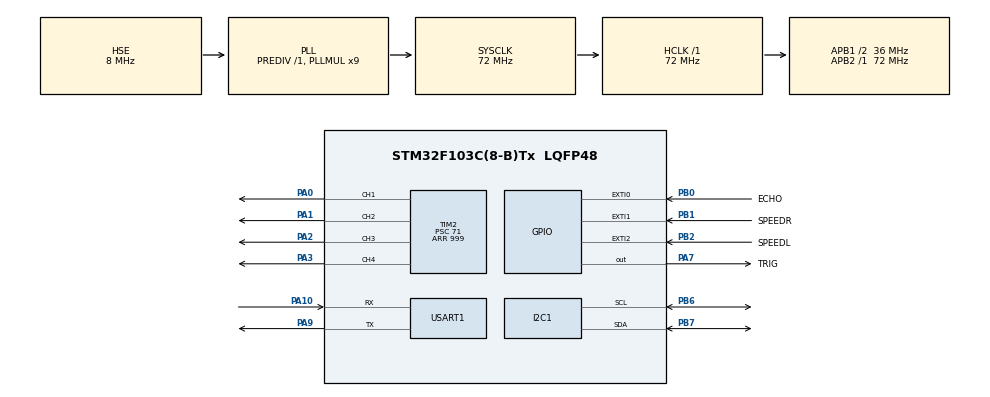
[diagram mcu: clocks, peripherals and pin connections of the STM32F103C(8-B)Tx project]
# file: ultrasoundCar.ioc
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IWDG.Prescaler=IWDG_PRESCALER_32
Mcu.Family=STM32F1
Mcu.Name=STM32F103C(8-B)Tx
Mcu.Package=LQFP48
NVIC.PriorityGroup=NVIC_PRIORITYGROUP_4
NVIC.TIM3_IRQn=true\:0\:0\:false\:false\:true
PA0-WKUP.Signal=S_TIM2_CH1_ETR
PA1.Signal=S_TIM2_CH2
PA10.Mode=Asynchronous
PA10.Signal=USART1_RX
PA13.Mode=Serial_Wire
PA13.Signal=SYS_JTMS-SWDIO
PA14.Mode=Serial_Wire
PA14.Signal=SYS_JTCK-SWCLK
PA2.Signal=S_TIM2_CH3
PA3.Signal=S_TIM2_CH4
PA7.GPIO_Label=TRIG
PA7.Signal=GPIO_Output
PA9.Mode=Asynchronous
PA9.Signal=USART1_TX
PB0.GPIO_Label=ECHO
PB0.Signal=GPXTI0
PB1.GPIO_Label=SPEEDR
PB1.Signal=GPXTI1
PB2.GPIO_Label=SPEEDL
PB2.Signal=GPXTI2
PB6.Mode=I2C
PB6.Signal=I2C1_SCL
PB7.Mode=I2C
PB7.Signal=I2C1_SDA
PD0-OSC_IN.Mode=HSE-External-Oscillator
PD0-OSC_IN.Signal=RCC_OSC_IN
PD1-OSC_OUT.Mode=HSE-External-Oscillator
PD1-OSC_OUT.Signal=RCC_OSC_OUT
ProjectManager.HeapSize=0x200
ProjectManager.StackSize=0x400
ProjectManager.TargetToolchain=SW4STM32
RCC.AHBFreq_Value=72000000
RCC.APB1CLKDivider=RCC_HCLK_DIV2
RCC.APB1Freq_Value=36000000
RCC.APB1TimFreq_Value=72000000
RCC.APB2Freq_Value=72000000
RCC.APB2TimFreq_Value=72000000
RCC.HCLKFreq_Value=72000000
RCC.HSIState=RCC_HSI_ON
RCC.PLLMUL=RCC_PLL_MUL9
RCC.PLLSourceVirtual=RCC_PLLSOURCE_HSE
RCC.SYSCLKFreq_VALUE=72000000
RCC.SYSCLKSource=RCC_SYSCLKSOURCE_PLLCLK
RCC.USBFreq_Value=72000000
SH.S_TIM2_CH1_ETR.0=TIM2_CH1,PWM Generation1 CH1
SH.S_TIM2_CH2.0=TIM2_CH2,PWM Generation2 CH2
SH.S_TIM2_CH3.0=TIM2_CH3,PWM Generation3 CH3
SH.S_TIM2_CH4.0=TIM2_CH4,PWM Generation4 CH4
TIM2.Channel-PWM\ Generation2\ CH2=TIM_CHANNEL_2
TIM2.Channel-PWM\ Generation3\ CH3=TIM_CHANNEL_3
TIM2.Channel-PWM\ Generation4\ CH4=TIM_CHANNEL_4
TIM2.Period=999
TIM2.Prescaler=71
TIM2.Pulse-PWM\ Generation1\ CH1=0
TIM2.Pulse-PWM\ Generation4\ CH4=0
VP_IWDG_VS_IWDG.Mode=IWDG_Activate
VP_TIM1_VS_ClockSourceINT.Mode=Internal
VP_TIM3_VS_ClockSourceINT.Mode=Internal
VP_TIM4_VS_ClockSourceINT.Mode=Internal
board=ultrasoundCar

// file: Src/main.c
/**
  ******************************************************************************
  * File Name          : main.c
  * Description        : Main program body
  ******************************************************************************
  *
  * COPYRIGHT(c) 2016 STMicroelectronics
  *
  * Redistribution and use in source and binary forms, with or without modification,
  * are permitted provided that the following conditions are met:
  *   1. Redistributions of source code must retain the above copyright notice,
  *      this list of conditions and the following disclaimer.
  *   2. Redistributions in binary form must reproduce the above copyright notice,
  *      this list of conditions and the following disclaimer in the documentation
  *      and/or other materials provided with the distribution.
  *   3. Neither the name of STMicroelectronics nor the names of its contributors
  *      may be used to endorse or promote products derived from this software
  *      without specific prior written permission.
  *
  * THIS SOFTWARE IS PROVIDED BY THE COPYRIGHT HOLDERS AND CONTRIBUTORS "AS IS"
  * AND ANY EXPRESS OR IMPLIED WARRANTIES, INCLUDING, BUT NOT LIMITED TO, THE
  * IMPLIED WARRANTIES OF MERCHANTABILITY AND FITNESS FOR A PARTICULAR PURPOSE ARE
  * DISCLAIMED. IN NO EVENT SHALL THE COPYRIGHT HOLDER OR CONTRIBUTORS BE LIABLE
  * FOR ANY DIRECT, INDIRECT, INCIDENTAL, SPECIAL, EXEMPLARY, OR CONSEQUENTIAL
  * DAMAGES (INCLUDING, BUT NOT LIMITED TO, PROCUREMENT OF SUBSTITUTE GOODS OR
  * SERVICES; LOSS OF USE, DATA, OR PROFITS; OR BUSINESS INTERRUPTION) HOWEVER
  * CAUSED AND ON ANY THEORY OF LIABILITY, WHETHER IN CONTRACT, STRICT LIABILITY,
  * OR TORT (INCLUDING NEGLIGENCE OR OTHERWISE) ARISING IN ANY WAY OUT OF THE USE
  * OF THIS SOFTWARE, EVEN IF ADVISED OF THE POSSIBILITY OF SUCH DAMAGE.
  *
  ******************************************************************************
  */
#include "stm32f1xx_hal.h"
#include "i2c.h"
#include "iwdg.h"
#include "tim.h"
#include "usart.h"
#include "gpio.h"

/* USER CODE BEGIN PV */
/* Private variables ---------------------------------------------------------*/

/* USER CODE END PV */

void SystemClock_Config(void);
void Error_Handler(void);

/* USER CODE BEGIN PFP */
/* Private function prototypes -----------------------------------------------*/

/* USER CODE END PFP */

int main(void)
{

  /* MCU Configuration----------------------------------------------------------*/

  /* Reset of all peripherals, Initializes the Flash interface and the Systick. */
  HAL_Init();

  /* Configure the system clock */
  SystemClock_Config();

  /* Initialize all configured peripherals */
  MX_GPIO_Init();
  MX_I2C1_Init();
  MX_IWDG_Init();
  MX_TIM2_Init();
  MX_TIM3_Init();
  MX_USART1_UART_Init();
  MX_TIM1_Init();
  MX_TIM4_Init();

  /* USER CODE BEGIN 2 */
  HAL_IWDG_Start(&hiwdg);//启用看门狗
  HAL_TIM_PWM_Start(&htim2,TIM_CHANNEL_ALL);
  /* USER CODE END 2 */

  /* Infinite loop */
  while (1)
  {

  /* USER CODE BEGIN 3 */

	  HAL_IWDG_Refresh(&hiwdg);//喂狗
  }
  /* USER CODE END 3 */

}

/** System Clock Configuration
*/
void SystemClock_Config(void)
{

  RCC_OscInitTypeDef RCC_OscInitStruct;
  RCC_ClkInitTypeDef RCC_ClkInitStruct;

  RCC_OscInitStruct.OscillatorType = RCC_OSCILLATORTYPE_LSI|RCC_OSCILLATORTYPE_HSE;
  RCC_OscInitStruct.HSEState = RCC_HSE_ON;
  RCC_OscInitStruct.HSEPredivValue = RCC_HSE_PREDIV_DIV1;
  RCC_OscInitStruct.LSIState = RCC_LSI_ON;
  RCC_OscInitStruct.PLL.PLLState = RCC_PLL_ON;
  RCC_OscInitStruct.PLL.PLLSource = RCC_PLLSOURCE_HSE;
  RCC_OscInitStruct.PLL.PLLMUL = RCC_PLL_MUL9;
  if (HAL_RCC_OscConfig(&RCC_OscInitStruct) != HAL_OK)
  {
    Error_Handler();
  }

  RCC_ClkInitStruct.ClockType = RCC_CLOCKTYPE_HCLK|RCC_CLOCKTYPE_SYSCLK
                              |RCC_CLOCKTYPE_PCLK1|RCC_CLOCKTYPE_PCLK2;
  RCC_ClkInitStruct.SYSCLKSource = RCC_SYSCLKSOURCE_PLLCLK;
  RCC_ClkInitStruct.AHBCLKDivider = RCC_SYSCLK_DIV1;
  RCC_ClkInitStruct.APB1CLKDivider = RCC_HCLK_DIV2;
  RCC_ClkInitStruct.APB2CLKDivider = RCC_HCLK_DIV1;
  if (HAL_RCC_ClockConfig(&RCC_ClkInitStruct, FLASH_LATENCY_2) != HAL_OK)
  {
    Error_Handler();
  }

  HAL_SYSTICK_Config(HAL_RCC_GetHCLKFreq()/1000);

  HAL_SYSTICK_CLKSourceConfig(SYSTICK_CLKSOURCE_HCLK);

  /* SysTick_IRQn interrupt configuration */
  HAL_NVIC_SetPriority(SysTick_IRQn, 0, 0);
}

void Error_Handler(void)
{
  while(1)
  {
  }
}

/************************ (C) COPYRIGHT STMicroelectronics *****END OF FILE****/
